# PIC32MK0512MCF064 register map
Vendor: Microchip
Registers are 32-bit, read-write, reset 0x0 unless marked. A register's access mark holds for its fields unless they carry their own. Addresses are absolute, and some are shared; only a register's first bit layout is shown; [hi:lo] are bit positions; {n}, {i} and the like mark numbered series.

## cmp_control_upb
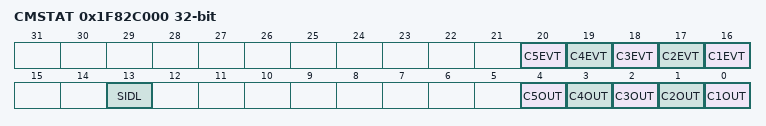
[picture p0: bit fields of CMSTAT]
0x1F82C000 CMSTAT
  [n+15] C{n}EVT ro (n=1..5), [13] SIDL, [n-1] C{n}OUT ro (n=1..5)

## CMP1
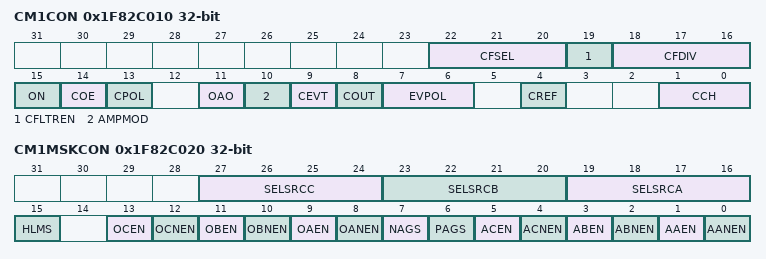
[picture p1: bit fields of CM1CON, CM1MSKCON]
0x1F82C010 CM1CON
  [22:20] CFSEL, [19] CFLTREN, [18:16] CFDIV, [15] ON, [14] COE, [13] CPOL, [11] OAO, [10] AMPMOD, [9] CEVT, [8] COUT ro, [7:6] EVPOL, [4] CREF, [1:0] CCH
0x1F82C020 CM1MSKCON
  [27:24] SELSRCC, [23:20] SELSRCB, [19:16] SELSRCA, [15] HLMS, [13] OCEN, [12] OCNEN, [11] OBEN, [10] OBNEN, [9] OAEN, [8] OANEN, [7] NAGS, [6] PAGS, [5] ACEN, [4] ACNEN, [3] ABEN, [2] ABNEN, [1] AAEN, [0] AANEN

## CMP2
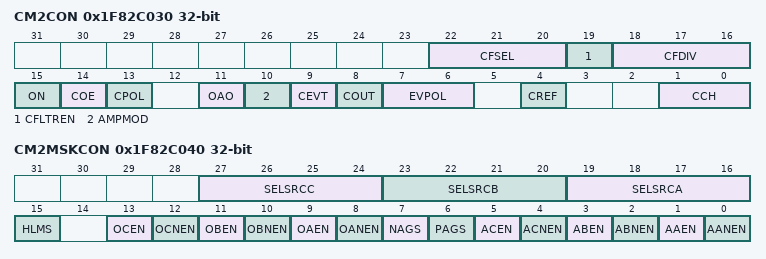
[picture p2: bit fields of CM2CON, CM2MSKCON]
0x1F82C030 CM2CON
  [22:20] CFSEL, [19] CFLTREN, [18:16] CFDIV, [15] ON, [14] COE, [13] CPOL, [11] OAO, [10] AMPMOD, [9] CEVT, [8] COUT ro, [7:6] EVPOL, [4] CREF, [1:0] CCH
0x1F82C040 CM2MSKCON
  [27:24] SELSRCC, [23:20] SELSRCB, [19:16] SELSRCA, [15] HLMS, [13] OCEN, [12] OCNEN, [11] OBEN, [10] OBNEN, [9] OAEN, [8] OANEN, [7] NAGS, [6] PAGS, [5] ACEN, [4] ACNEN, [3] ABEN, [2] ABNEN, [1] AAEN, [0] AANEN

## CMP3
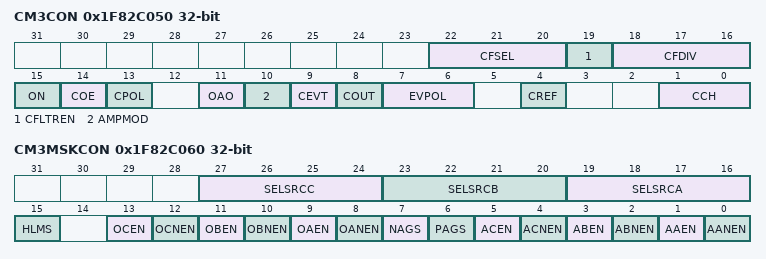
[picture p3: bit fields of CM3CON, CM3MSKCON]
0x1F82C050 CM3CON
  [22:20] CFSEL, [19] CFLTREN, [18:16] CFDIV, [15] ON, [14] COE, [13] CPOL, [11] OAO, [10] AMPMOD, [9] CEVT, [8] COUT ro, [7:6] EVPOL, [4] CREF, [1:0] CCH
0x1F82C060 CM3MSKCON
  [27:24] SELSRCC, [23:20] SELSRCB, [19:16] SELSRCA, [15] HLMS, [13] OCEN, [12] OCNEN, [11] OBEN, [10] OBNEN, [9] OAEN, [8] OANEN, [7] NAGS, [6] PAGS, [5] ACEN, [4] ACNEN, [3] ABEN, [2] ABNEN, [1] AAEN, [0] AANEN

## CMP4
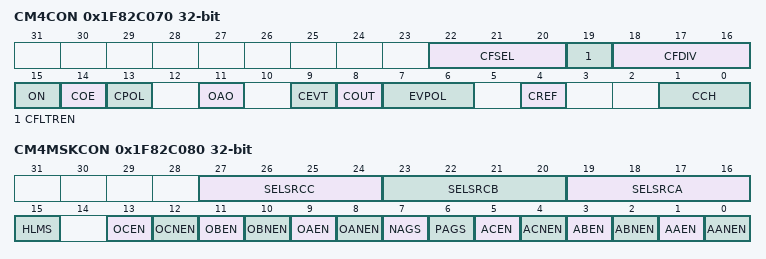
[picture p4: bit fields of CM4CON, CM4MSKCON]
0x1F82C070 CM4CON
  [22:20] CFSEL, [19] CFLTREN, [18:16] CFDIV, [15] ON, [14] COE, [13] CPOL, [11] OAO, [9] CEVT, [8] COUT ro, [7:6] EVPOL, [4] CREF, [1:0] CCH
0x1F82C080 CM4MSKCON
  [27:24] SELSRCC, [23:20] SELSRCB, [19:16] SELSRCA, [15] HLMS, [13] OCEN, [12] OCNEN, [11] OBEN, [10] OBNEN, [9] OAEN, [8] OANEN, [7] NAGS, [6] PAGS, [5] ACEN, [4] ACNEN, [3] ABEN, [2] ABNEN, [1] AAEN, [0] AANEN

## CMP5
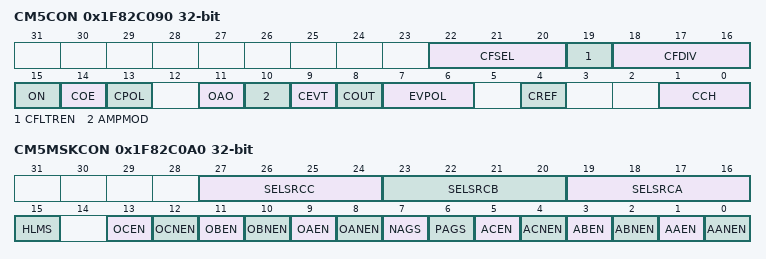
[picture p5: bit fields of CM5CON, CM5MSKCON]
0x1F82C090 CM5CON
  [22:20] CFSEL, [19] CFLTREN, [18:16] CFDIV, [15] ON, [14] COE, [13] CPOL, [11] OAO, [10] AMPMOD, [9] CEVT, [8] COUT ro, [7:6] EVPOL, [4] CREF, [1:0] CCH
0x1F82C0A0 CM5MSKCON
  [27:24] SELSRCC, [23:20] SELSRCB, [19:16] SELSRCA, [15] HLMS, [13] OCEN, [12] OCNEN, [11] OBEN, [10] OBNEN, [9] OAEN, [8] OANEN, [7] NAGS, [6] PAGS, [5] ACEN, [4] ACNEN, [3] ABEN, [2] ABNEN, [1] AAEN, [0] AANEN

## CDAC1
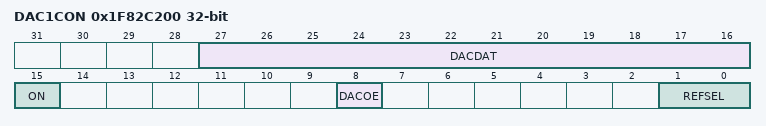
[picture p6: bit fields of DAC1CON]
0x1F82C200 DAC1CON — CDAC Control Register
  [27:16] DACDAT — Data Input Register Bits for the CDAC
  [15] ON — CDAC Enable
    0=The CDAC is Disabled; 1=The CDAC is Enabled
  [8] DACOE — CDAC Output Enable
    0=Output is Disabled; drive to pin is floating; 1=Output is Enabled; CDAC voltage is connected to the pin
  [1:0] REFSEL — Reference Source Select
    0=No Reference Selected (no current consumed); 1=Positive Reference Voltage = External Vref+ Pin; 2=Positive Reference Voltage = 2 * Internal Bandgap Reference Voltage; 3=Positive Reference Voltage = AVdd

## CTMU
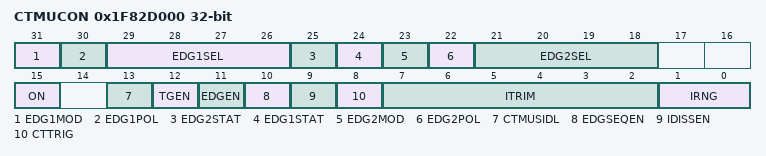
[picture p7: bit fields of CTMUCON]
0x1F82D000 CTMUCON
  [31] EDG1MOD, [30] EDG1POL, [29:26] EDG1SEL, [25] EDG2STAT, [24] EDG1STAT, [23] EDG2MOD, [22] EDG2POL, [21:18] EDG2SEL, [15] ON, [13] CTMUSIDL, [12] TGEN, [11] EDGEN, [10] EDGSEQEN, [9] IDISSEN, [8] CTTRIG, [7:2] ITRIM, [1:0] IRNG

## PMP
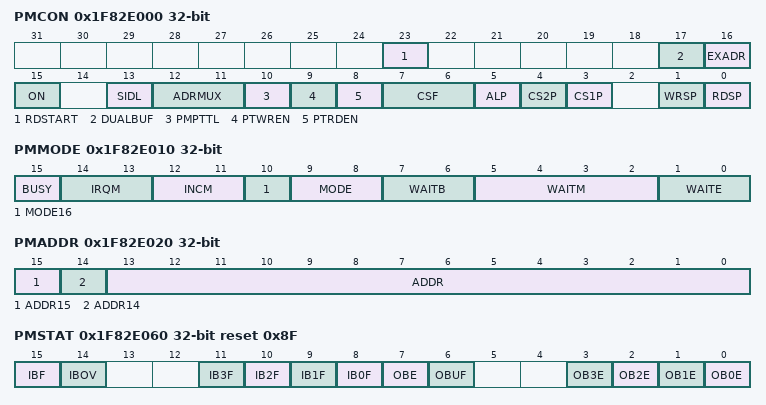
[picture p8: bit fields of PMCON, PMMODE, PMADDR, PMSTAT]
0x1F82E000 PMCON reset not defined — (power-on value --------x-----xx00000-0000000-00)
  [23] RDSTART, [17] DUALBUF, [16] EXADR, [15] ON, [13] SIDL, [12:11] ADRMUX, [10] PMPTTL, [9] PTWREN, [8] PTRDEN, [7:6] CSF, [5] ALP, [4] CS2P, [3] CS1P, [1] WRSP, [0] RDSP
0x1F82E010 PMMODE
  [15] BUSY, [14:13] IRQM, [12:11] INCM, [10] MODE16, [9:8] MODE, [7:6] WAITB, [5:2] WAITM, [1:0] WAITE
0x1F82E020 PMADDR reset not defined — (power-on value ----------------xxxxxxxxxxxxxxxx)
  [15] ADDR15, [14] ADDR14, [13:0] ADDR
0x1F82E030 PMDOUT reset not defined — (power-on value xxxxxxxxxxxxxxxxxxxxxxxxxxxxxxxx)
  [31:0] DATAOUT
0x1F82E040 PMDIN reset not defined — (power-on value xxxxxxxxxxxxxxxxxxxxxxxxxxxxxxxx)
  [31:0] DATAIN
0x1F82E050 PMAEN reset not defined — (power-on value --------xxxxxxxxxxxxxxxxxxxxxxxx)
  [23:0] PTEN
0x1F82E060 PMSTAT reset 0x8F
  [15] IBF ro, [14] IBOV, [n+8] IB{n}F ro (n=0..3), [7] OBE ro, [6] OBUF, [n] OB{n}E ro (n=0..3)
0x1F82E070 PMWADDR reset not defined — (power-on value --------xxxxxxxxxxxxxxxxxxxxxxxx)
  [23:0] WADDR
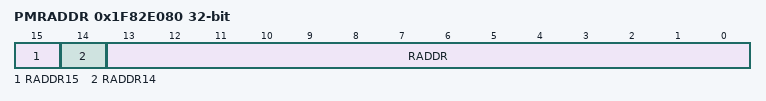
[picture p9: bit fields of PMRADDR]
0x1F82E080 PMRADDR reset not defined — (power-on value ----------------xxxxxxxxxxxxxxxx)
  [15] RADDR15, [14] RADDR14, [13:0] RADDR
0x1F82E090 PMRDIN reset not defined — (power-on value xxxxxxxxxxxxxxxxxxxxxxxxxxxxxxxx)
  [31:0] RDATAIN
